# STM32H7RSxx register map
File version: 0.2
CPU: CM7 r0p1, little endian, MPU, FPU, 4 interrupt priority bits
Registers are 32-bit, read-write, reset 0x0 unless marked. A register's access mark holds for its fields unless they carry their own. Offsets are from the block's base; [hi:lo] are bit positions; {n}, {i} and the like mark numbered series.

## MDIOS — Management data input/output
Base 0x40009400
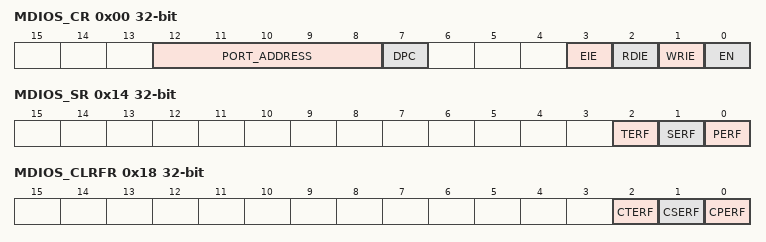
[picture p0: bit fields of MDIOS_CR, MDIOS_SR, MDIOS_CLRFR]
0x00 MDIOS_CR — MDIOS configuration register
  [12:8] PORT_ADDRESS — slave address Can be written only when the peripheral is disabled (EN = 0). If the address given by the MDIO master matches PORT_ADRESS[4:0], then the MDIOS services the frame. Otherwise the frame is ignored.
  [7] DPC — disable preamble check Note: When this bit is set, the application must be sure that no frame is currently in progress when the MDIOS is enabled. Otherwise, the MDIOS can become desynchronized with the master. Note: This bit cannot be changed unless EN = 0 (though it can be changed at the same time that EN is being set).
    0=MDIO master must give preamble before each frame; 1=MDIO master can send each frame without a preceding preamble, and the MDIOS does not signal a preamble error
  [3] EIE — error interrupt enable Note: When this bit is set, an interrupt is generated if any of the error flags (PERF, SERF, or TERF in the MDIOS_SR register) is set.
    0=Interrupt is disabled; 1=Interrupt is enabled
  [2] RDIE — register read interrupt enable Note: When this bit is set, an interrupt is generated if any of the read flags (RDF[31:0] in the MDIOS_RDFR register) is set.
    0=Interrupt is disabled; 1=Interrupt is enabled
  [1] WRIE — register write interrupt enable Note: When this bit is set, an interrupt is generated if any of the read flags (WRF[31:0] in the MDIOS_WRFR register) is set.
    0=Interrupt is disabled; 1=Interrupt is enabled
  [0] EN — peripheral enable
    0=MDIOS is disabled; 1=MDIOS is enabled and monitoring the MDIO bus (MDC/MDIO)
0x04 MDIOS_WRFR ro — MDIOS write flag register
  [31:0] WRF — write flags for MDIOS registers 0 to 31. Each bit is set by hardware when the MDIO master performs a write to the corresponding MDIOS register. An interrupt is generated if WRIE (in MDIOS_CR) is set. Each bit is cleared by software by writing ‘1’ to the corresponding CWRF bit in the MDIOS_CWRFR register. For WRFx:
    0=MDIOS register x is not written by the MDIO master; 1=MDIOS register x is written by the MDIO master and the data is available in DIN[15:0] in the MDIOS_DINRx register
0x08 MDIOS_CWRFR — MDIOS clear write flag register
  [31:0] CWRF — clear the write flag Writing 1 to CWRFx clears the WRFx bit in the MDIOS_WRF register.
0x0C MDIOS_RDFR ro — MDIOS read flag register
  [31:0] RDF — read flags for MDIOS registers 0 to 31. Each bit is set by hardware when the MDIO master performs a read from the corresponding MDIOS register. An interrupt is generated if RDIE (in MDIOS_CR) is set. Each bit is cleared by software by writing ‘1’ to the corresponding CRDF bit in the MDIOS_CRDFR register. For RDFx:
    0=MDIOS register x is not read by the MDIO master; 1=MDIOS register x is read by the MDIO master
0x10 MDIOS_CRDFR — MDIOS clear read flag register
  [31:0] CRDF — clear the read flag Writing 1 to CRDFx clears the RDFx bit in the MDIOS_RDF register.
0x14 MDIOS_SR ro — MDIOS status register
  [2] TERF — turnaround error flag Note: Writing 1 to CTERF (MDIOS_CLRFR) clears this bit.
    0=No turnaround error has occurred; 1=A turnaround error has occurred
  [1] SERF — start error flag Note: Writing 1 to CSERF (MDIOS_CLRFR) clears this bit.
    0=No start error has occurred; 1=A start error has occurred
  [0] PERF — preamble error flag Note: Writing 1 to CPERF (MDIOS_CLRFR) clears this bit. Note: This bit is not set if DPC (disable preamble check, MDIOS_CR[7]) is set.
    0=No preamble error has occurred; 1=A preamble error has occurred
0x18 MDIOS_CLRFR — MDIOS clear flag register
  [2] CTERF — clear the turnaround error flag Writing 1 to this bit clears the TERF flag (in MDIOS_SR). When DPC = 1 (MDIOS_CR[7]), the TERF flag must be cleared only when there is not a frame already in progress.
  [1] CSERF — clear the start error flag Writing 1 to this bit clears the SERF flag (in MDIOS_SR). When DPC = 1 (MDIOS_CR[7]), the SERF flag must be cleared only when there is not a frame already in progress.
  [0] CPERF — clear the preamble error flag Writing 1 to this bit clears the PERF flag (in MDIOS_SR).
{0x100+4i} MDIOS_DINR{i} ro (i=0..31) — MDIOS input data register {i}
  [15:0] DIN — input data received from MDIO master during write frames This field is written by hardware with the 16-bit data received in a write frame which is addressed to MDIOS register x.
{0x180+4i} MDIOS_DOUTR{i} (i=0..31) — MDIOS output data register {i}
  [15:0] DOUT — output data sent to MDIO Master during read frames This field is written by software. These 16 bits are serially output on the MDIO bus during read frames which address the MDIOS register x.
